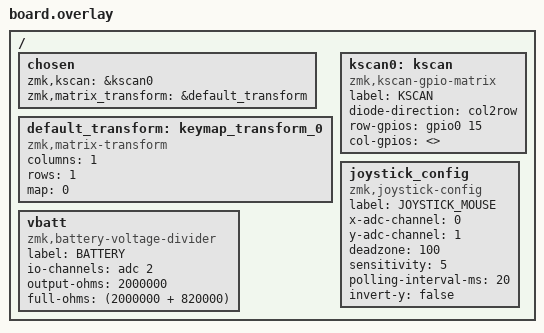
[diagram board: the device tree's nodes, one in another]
/dts-v1/;
/plugin/;

#include <dt-bindings/zmk/matrix_transform.h>

/ {
	chosen {
		zmk,kscan = &kscan0;
		zmk,matrix_transform = &default_transform;
	};

	// 虚拟键盘矩阵（无实际按键）
	default_transform: keymap_transform_0 {
		compatible = "zmk,matrix-transform";
		columns = <1>;
		rows = <1>;
		map = <0>;
	};

	kscan0: kscan {
		compatible = "zmk,kscan-gpio-matrix";
		label = "KSCAN";
		diode-direction = "col2row";
		row-gpios = <&gpio0 15 (GPIO_ACTIVE_HIGH | GPIO_PULL_DOWN)>;
		col-gpios = <>;
	};
	
	joystick_config: joystick_config {
		compatible = "zmk,joystick-config";
		status = "okay";
		label = "JOYSTICK_MOUSE";
		
		// ADC通道
		x-adc-channel = <0>;  // AIN0 (P0.02)
		y-adc-channel = <1>;  // AIN1 (P0.03)
		
		// 配置参数
		deadzone = <100>;
		sensitivity = <5>;
		polling-interval-ms = <20>;
		invert-y = <false>;
	};
	
	// 电池配置
	vbatt: vbatt {
		compatible = "zmk,battery-voltage-divider";
		label = "BATTERY";
		io-channels = <&adc 2>;
		output-ohms = <2000000>;
		full-ohms = <(2000000 + 820000)>;
	};
};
